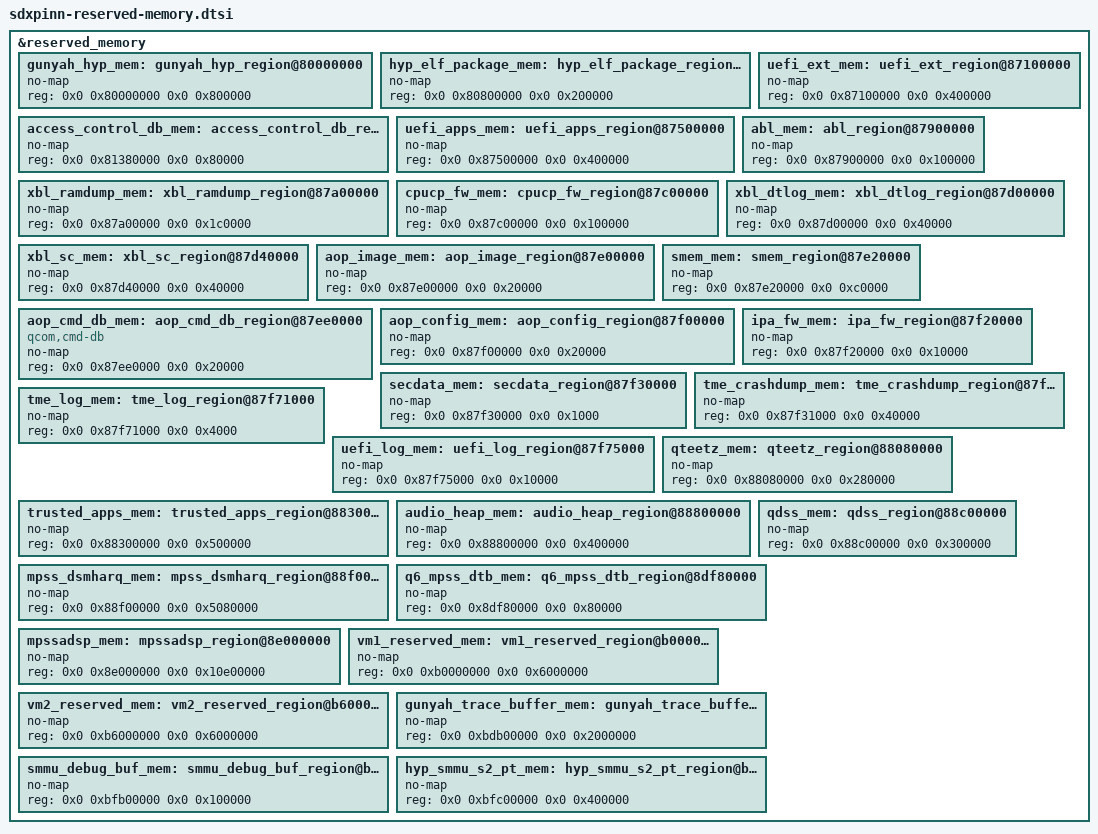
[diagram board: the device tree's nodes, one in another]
&reserved_memory {
	#address-cells = <2>;
	#size-cells = <2>;
	ranges;

	gunyah_hyp_mem: gunyah_hyp_region@80000000 {
		no-map;
		reg = <0x0 0x80000000 0x0 0x800000>;
	};

	hyp_elf_package_mem: hyp_elf_package_region@80800000 {
		no-map;
		reg = <0x0 0x80800000 0x0 0x200000>;
	};

	access_control_db_mem: access_control_db_region@81380000 {
		no-map;
		reg = <0x0 0x81380000 0x0 0x80000>;
	};

	uefi_ext_mem: uefi_ext_region@87100000 {
		no-map;
		reg = <0x0 0x87100000 0x0 0x400000>;
	};

	uefi_apps_mem: uefi_apps_region@87500000 {
		no-map;
		reg = <0x0 0x87500000 0x0 0x400000>;
	};

	abl_mem: abl_region@87900000 {
		no-map;
		reg = <0x0 0x87900000 0x0 0x100000>;
	};

	xbl_ramdump_mem: xbl_ramdump_region@87a00000 {
		no-map;
		reg = <0x0 0x87a00000 0x0 0x1c0000>;
	};

	cpucp_fw_mem: cpucp_fw_region@87c00000 {
		no-map;
		reg = <0x0 0x87c00000 0x0 0x100000>;
	};

	xbl_dtlog_mem: xbl_dtlog_region@87d00000 {
		no-map;
		reg = <0x0 0x87d00000 0x0 0x40000>;
	};

	xbl_sc_mem: xbl_sc_region@87d40000 {
		no-map;
		reg = <0x0 0x87d40000 0x0 0x40000>;
	};

	aop_image_mem: aop_image_region@87e00000 {
		no-map;
		reg = <0x0 0x87e00000 0x0 0x20000>;
	};

	smem_mem: smem_region@87e20000 {
		no-map;
		reg = <0x0 0x87e20000 0x0 0xc0000>;
	};

	aop_cmd_db_mem: aop_cmd_db_region@87ee0000 {
		compatible = "qcom,cmd-db";
		no-map;
		reg = <0x0 0x87ee0000 0x0 0x20000>;
	};

	aop_config_mem: aop_config_region@87f00000 {
		no-map;
		reg = <0x0 0x87f00000 0x0 0x20000>;
	};

	ipa_fw_mem: ipa_fw_region@87f20000 {
		no-map;
		reg = <0x0 0x87f20000 0x0 0x10000>;
	};

	secdata_mem: secdata_region@87f30000 {
		no-map;
		reg = <0x0 0x87f30000 0x0 0x1000>;
	};

	tme_crashdump_mem: tme_crashdump_region@87f31000 {
		no-map;
		reg = <0x0 0x87f31000 0x0 0x40000>;
	};

	tme_log_mem: tme_log_region@87f71000 {
		no-map;
		reg = <0x0 0x87f71000 0x0 0x4000>;
	};

	uefi_log_mem: uefi_log_region@87f75000 {
		no-map;
		reg = <0x0 0x87f75000 0x0 0x10000>;
	};

	qteetz_mem: qteetz_region@88080000 {
		no-map;
		reg = <0x0 0x88080000 0x0 0x280000>;
	};

	trusted_apps_mem: trusted_apps_region@88300000 {
		no-map;
		reg = <0x0 0x88300000 0x0 0x500000>;
	};

	audio_heap_mem: audio_heap_region@88800000 {
		no-map;
		reg = <0x0 0x88800000 0x0 0x400000>;
	};

	qdss_mem: qdss_region@88c00000 {
		no-map;
		reg = <0x0 0x88c00000 0x0 0x300000>;
	};

	mpss_dsmharq_mem: mpss_dsmharq_region@88f00000 {
		no-map;
		reg = <0x0 0x88f00000 0x0 0x5080000>;
	};

	q6_mpss_dtb_mem: q6_mpss_dtb_region@8df80000 {
		no-map;
		reg = <0x0 0x8df80000 0x0 0x80000>;
	};

	mpssadsp_mem: mpssadsp_region@8e000000 {
		no-map;
		reg = <0x0 0x8e000000 0x0 0x10e00000>;
	};

	vm1_reserved_mem: vm1_reserved_region@b0000000 {
		no-map;
		reg = <0x0 0xb0000000 0x0 0x6000000>;
	};

	vm2_reserved_mem: vm2_reserved_region@b6000000 {
		no-map;
		reg = <0x0 0xb6000000 0x0 0x6000000>;
	};

	gunyah_trace_buffer_mem: gunyah_trace_buffer_region@bdb00000 {
		no-map;
		reg = <0x0 0xbdb00000 0x0 0x2000000>;
	};

	smmu_debug_buf_mem: smmu_debug_buf_region@bfb00000 {
		no-map;
		reg = <0x0 0xbfb00000 0x0 0x100000>;
	};

	hyp_smmu_s2_pt_mem: hyp_smmu_s2_pt_region@bfc00000 {
		no-map;
		reg = <0x0 0xbfc00000 0x0 0x400000>;
	};

};
